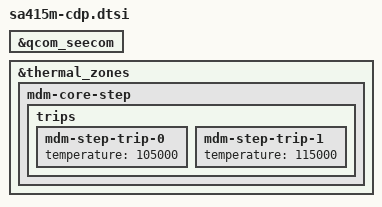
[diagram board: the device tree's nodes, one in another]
/* Copyright (c) 2020, The Linux Foundation. All rights reserved.
 *
 * This program is free software; you can redistribute it and/or modify
 * it under the terms of the GNU General Public License version 2 and
 * only version 2 as published by the Free Software Foundation.
 *
 * This program is distributed in the hope that it will be useful,
 * but WITHOUT ANY WARRANTY; without even the implied warranty of
 * MERCHANTABILITY or FITNESS FOR A PARTICULAR PURPOSE.  See the
 * GNU General Public License for more details.
 */

#include "sdxpoorwills-cdp.dtsi"

&qcom_seecom {
	status = "okay";
};

&thermal_zones {
	mdm-core-step {
		trips {
			mdm-step-trip-0 {
				temperature = <105000>;
			};

			mdm-step-trip-1 {
				temperature = <115000>;
			};
		};
	};
};
